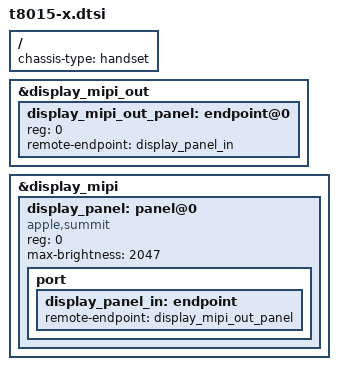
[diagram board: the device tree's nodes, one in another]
// SPDX-License-Identifier: GPL-2.0+ OR MIT
/*
 * Apple iPhone X common device tree
 *
 * Copyright (c) 2022, Konrad Dybcio <konradybcio@kernel.org>
 */

#include "t8015.dtsi"
#include "t8015-common.dtsi"

/ {
	chassis-type = "handset";
};

&display_mipi_out {
	display_mipi_out_panel: endpoint@0 {
		reg = <0>;
		remote-endpoint = <&display_panel_in>;
	};
};

&display_mipi {
	display_panel: panel@0 {
		compatible = "apple,summit";
		reg = <0>;
		max-brightness = <2047>;

		port {
			display_panel_in: endpoint {
				remote-endpoint = <&display_mipi_out_panel>;
			};
		};
	};
};
